VERSION "1"

NS_ :

BS_:

BU_: BMS EDGE

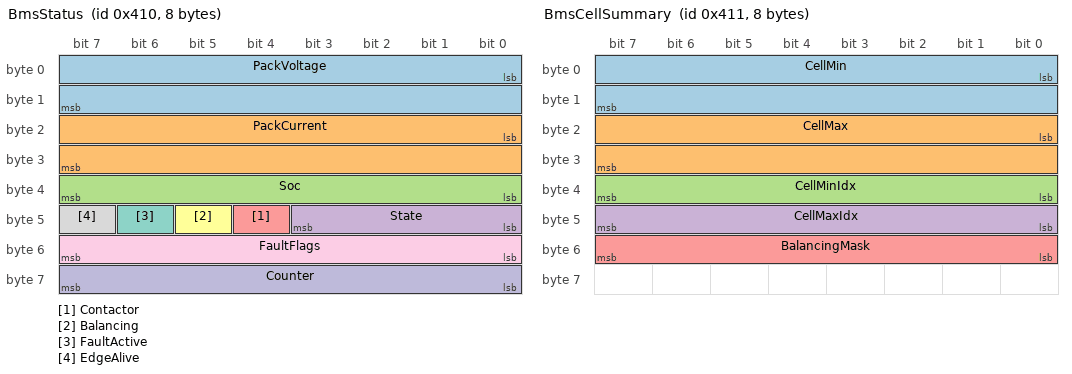
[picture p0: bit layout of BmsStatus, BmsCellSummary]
BO_ 1040 BmsStatus: 8 BMS
 SG_ PackVoltage : 0|16@1+ (0.01,0) [0|655.35] "V" EDGE
 SG_ PackCurrent : 16|16@1- (0.1,0) [-3276.8|3276.7] "A" EDGE
 SG_ Soc : 32|8@1+ (0.5,0) [0|100] "%" EDGE
 SG_ State : 40|4@1+ (1,0) [0|15] "" EDGE
 SG_ Contactor : 44|1@1+ (1,0) [0|1] "" EDGE
 SG_ Balancing : 45|1@1+ (1,0) [0|1] "" EDGE
 SG_ FaultActive : 46|1@1+ (1,0) [0|1] "" EDGE
 SG_ EdgeAlive : 47|1@1+ (1,0) [0|1] "" EDGE
 SG_ FaultFlags : 48|8@1+ (1,0) [0|255] "" EDGE
 SG_ Counter : 56|8@1+ (1,0) [0|255] "" EDGE

BO_ 1041 BmsCellSummary: 8 BMS
 SG_ CellMin : 0|16@1+ (1,0) [0|65535] "mV" EDGE
 SG_ CellMax : 16|16@1+ (1,0) [0|65535] "mV" EDGE
 SG_ CellMinIdx : 32|8@1+ (1,0) [0|255] "" EDGE
 SG_ CellMaxIdx : 40|8@1+ (1,0) [0|255] "" EDGE
 SG_ BalancingMask : 48|8@1+ (1,0) [0|255] "" EDGE

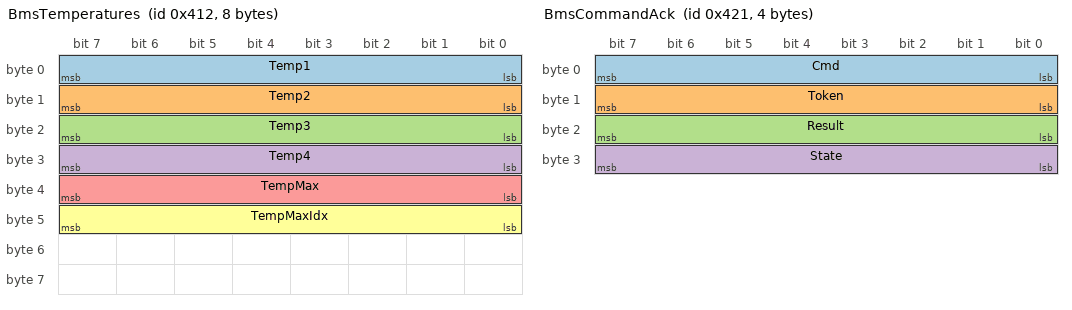
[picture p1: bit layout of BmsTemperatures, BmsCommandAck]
BO_ 1042 BmsTemperatures: 8 BMS
 SG_ Temp1 : 0|8@1+ (1,-40) [-40|215] "degC" EDGE
 SG_ Temp2 : 8|8@1+ (1,-40) [-40|215] "degC" EDGE
 SG_ Temp3 : 16|8@1+ (1,-40) [-40|215] "degC" EDGE
 SG_ Temp4 : 24|8@1+ (1,-40) [-40|215] "degC" EDGE
 SG_ TempMax : 32|8@1+ (1,-40) [-40|215] "degC" EDGE
 SG_ TempMaxIdx : 40|8@1+ (1,0) [0|255] "" EDGE

BO_ 1043 BmsCellVoltages: 8 BMS
 SG_ Group M : 0|8@1+ (1,0) [0|255] "" EDGE
 SG_ CellA m0 : 8|16@1+ (1,0) [0|65535] "mV" EDGE
 SG_ CellB m0 : 24|16@1+ (1,0) [0|65535] "mV" EDGE
 SG_ CellC m0 : 40|16@1+ (1,0) [0|65535] "mV" EDGE
 SG_ CellA m1 : 8|16@1+ (1,0) [0|65535] "mV" EDGE
 SG_ CellB m1 : 24|16@1+ (1,0) [0|65535] "mV" EDGE
 SG_ CellC m1 : 40|16@1+ (1,0) [0|65535] "mV" EDGE
 SG_ CellA m2 : 8|16@1+ (1,0) [0|65535] "mV" EDGE
 SG_ CellB m2 : 24|16@1+ (1,0) [0|65535] "mV" EDGE

BO_ 1055 BmsHeartbeat: 8 BMS
 SG_ Seq : 0|32@1+ (1,0) [0|4294967295] "" EDGE
 SG_ Uptime : 32|32@1+ (1,0) [0|4294967295] "s" EDGE

BO_ 1056 BmsCommand: 2 EDGE
 SG_ Cmd : 0|8@1+ (1,0) [0|255] "" BMS
 SG_ Token : 8|8@1+ (1,0) [0|255] "" BMS

BO_ 1057 BmsCommandAck: 4 BMS
 SG_ Cmd : 0|8@1+ (1,0) [0|255] "" EDGE
 SG_ Token : 8|8@1+ (1,0) [0|255] "" EDGE
 SG_ Result : 16|8@1+ (1,0) [0|255] "" EDGE
 SG_ State : 24|8@1+ (1,0) [0|255] "" EDGE

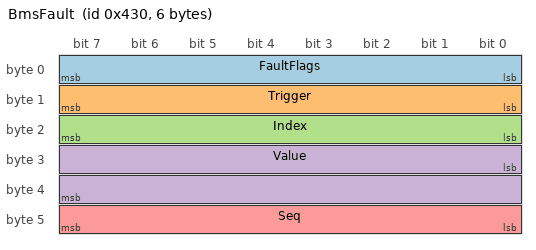
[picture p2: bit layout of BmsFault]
BO_ 1072 BmsFault: 6 BMS
 SG_ FaultFlags : 0|8@1+ (1,0) [0|255] "" EDGE
 SG_ Trigger : 8|8@1+ (1,0) [0|255] "" EDGE
 SG_ Index : 16|8@1+ (1,0) [0|255] "" EDGE
 SG_ Value : 24|16@1- (1,0) [-32768|32767] "" EDGE
 SG_ Seq : 40|8@1+ (1,0) [0|255] "" EDGE

CM_ BO_ 1040 "Pack status, every 100 ms. Current is positive when discharging";
CM_ BO_ 1041 "Lowest and highest cell, every 500 ms";
CM_ BO_ 1042 "Four temperature sensors, every 500 ms";
CM_ BO_ 1043 "All cell voltages, multiplexed three per frame (Group 0..2 = cells 1-3, 4-6, 7-8), every 1 s";
CM_ BO_ 1055 "BMS heartbeat, every 1 s";
CM_ BO_ 1056 "Command from the edge controller to the BMS";
CM_ BO_ 1057 "BMS answer to BmsCommand: same Cmd and Token, Result, and the state afterwards";
CM_ BO_ 1072 "Sent when a fault is raised and every 1 s while one is active";
CM_ SG_ 1040 EdgeAlive "1 while the edge controller's heartbeat (0x101, edge-linux-can can-demo) was seen in the last 3 s";
CM_ SG_ 1040 FaultFlags "Bit 0 over-voltage, bit 1 under-voltage, bit 2 over-temperature, bit 3 over-current";
CM_ SG_ 1041 BalancingMask "Bit n = cell n+1 is being bled";
CM_ SG_ 1072 Value "Cell voltage in mV for voltage faults, temperature in 0.1 degC for over-temperature";
CM_ SG_ 1056 Cmd "Sim* commands drive the simulated pack (a real BMS would not have them)";

VAL_ 1040 State 0 "Init" 1 "Standby" 2 "Active" 3 "Fault" ;
VAL_ 1056 Cmd 1 "ContactorClose" 2 "ContactorOpen" 3 "BalancingOn" 4 "BalancingOff" 5 "FaultReset" 16 "SimNormal" 17 "SimOverTemp" 18 "SimOverVoltage" 126 "SimHang" ;
VAL_ 1057 Cmd 1 "ContactorClose" 2 "ContactorOpen" 3 "BalancingOn" 4 "BalancingOff" 5 "FaultReset" 16 "SimNormal" 17 "SimOverTemp" 18 "SimOverVoltage" 126 "SimHang" ;
VAL_ 1057 Result 0 "Ok" 1 "Rejected" 2 "Unknown" ;
VAL_ 1057 State 0 "Init" 1 "Standby" 2 "Active" 3 "Fault" ;
VAL_ 1072 Trigger 1 "OverVoltage" 2 "UnderVoltage" 4 "OverTemp" 8 "OverCurrent" ;
